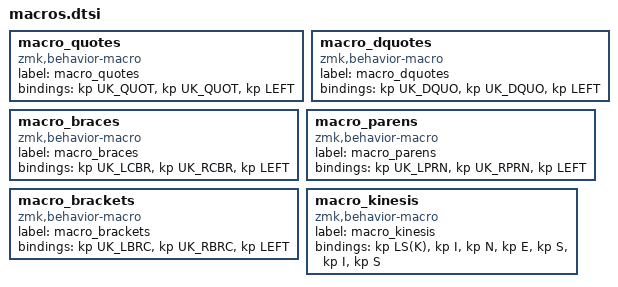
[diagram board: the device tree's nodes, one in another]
  macro_quotes: macro_quotes {
    compatible = "zmk,behavior-macro";
    label = "macro_quotes";
    #binding-cells = <0>;
    bindings = <&kp UK_QUOT>, <&kp UK_QUOT>, <&kp LEFT>;
  };
  macro_dquotes: macro_dquotes {
    compatible = "zmk,behavior-macro";
    label = "macro_dquotes";
    #binding-cells = <0>;
    bindings = <&kp UK_DQUO>, <&kp UK_DQUO>, <&kp LEFT>;
  };
  macro_braces: macro_braces {
    compatible = "zmk,behavior-macro";
    label = "macro_braces";
    #binding-cells = <0>;
    bindings = <&kp UK_LCBR>, <&kp UK_RCBR>, <&kp LEFT>;
  };
  macro_parens: macro_parens {
    compatible = "zmk,behavior-macro";
    label = "macro_parens";
    #binding-cells = <0>;
    bindings = <&kp UK_LPRN>, <&kp UK_RPRN>, <&kp LEFT>;
  };
  macro_brackets: macro_brackets {
    compatible = "zmk,behavior-macro";
    label = "macro_brackets";
    #binding-cells = <0>;
    bindings = <&kp UK_LBRC>, <&kp UK_RBRC>, <&kp LEFT>;
  };
  macro_kinesis: macro_kinesis {
    compatible = "zmk,behavior-macro";
    label = "macro_kinesis";
    #binding-cells = <0>;
    bindings = <&kp LS(K)>, <&kp I>, <&kp N>, <&kp E>, <&kp S>, <&kp I>, <&kp S>;
  };
